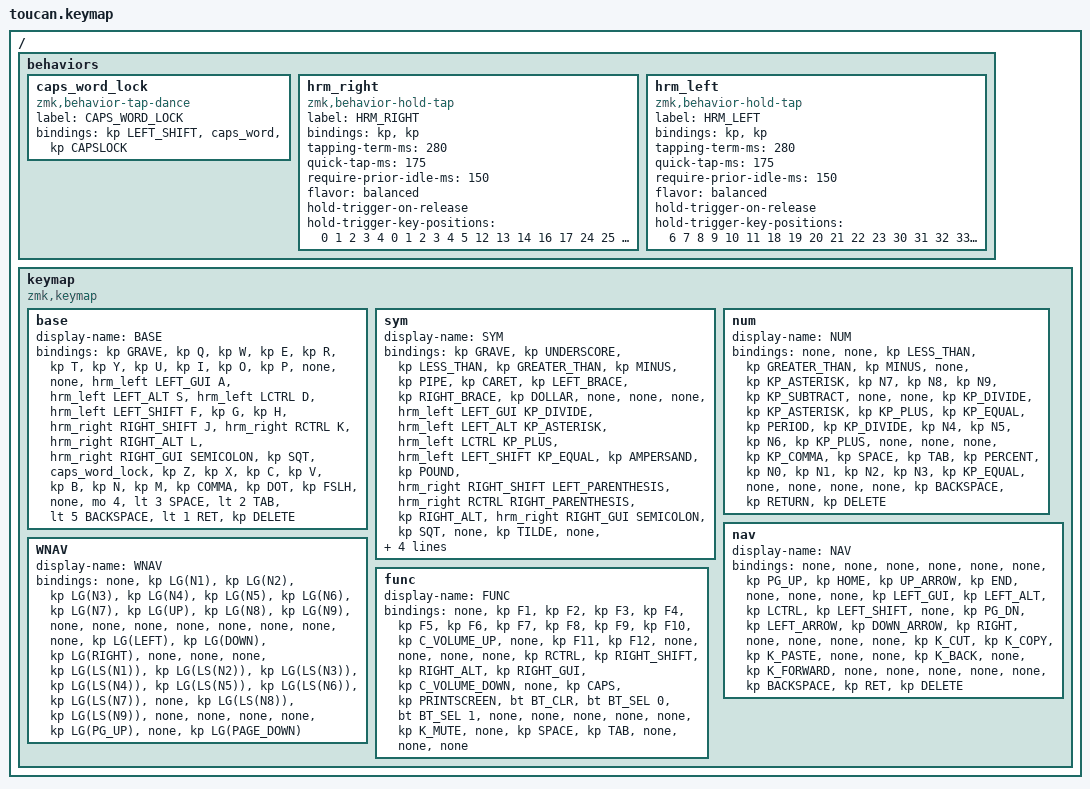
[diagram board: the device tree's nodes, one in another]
#include <behaviors.dtsi>
#include <dt-bindings/zmk/bt.h>
#include <dt-bindings/zmk/keys.h>

#define BASE 0
#define SYM  1
#define NUM  2
#define NAV  3
#define WNAV 4
#define FUNC 5

/ {
    behaviors {
        caps_word_lock: caps_word_lock {
            compatible = "zmk,behavior-tap-dance";
            label = "CAPS_WORD_LOCK";
            #binding-cells = <0>;
            bindings = <&kp LEFT_SHIFT>, <&caps_word>, <&kp CAPSLOCK>;
        };

        hrm_right: hrm_right {
            compatible = "zmk,behavior-hold-tap";
            label = "HRM_RIGHT";
            bindings = <&kp>, <&kp>;

            #binding-cells = <2>;
            tapping-term-ms = <280>;
            quick-tap-ms = <175>;
            require-prior-idle-ms = <150>;
            flavor = "balanced";
            hold-trigger-on-release;
            hold-trigger-key-positions = <0 1 2 3 4 0 1 2 3 4 5 12 13 14 16 17 24 25 26 27 28 29 0 1 2 14 15 36 37 38 39 40 41>;
        };

        hrm_left: hrm_left {
            compatible = "zmk,behavior-hold-tap";
            label = "HRM_LEFT";
            bindings = <&kp>, <&kp>;

            #binding-cells = <2>;
            tapping-term-ms = <280>;
            quick-tap-ms = <175>;
            require-prior-idle-ms = <150>;
            flavor = "balanced";
            hold-trigger-on-release;
            hold-trigger-key-positions = <6 7 8 9 10 11 18 19 20 21 22 23 30 31 32 33 34 35 38 39 40 41 36 37>;
        };
    };

    keymap {
        compatible = "zmk,keymap";

        base {
            display-name = "BASE";
            bindings = <
&kp GRAVE  &kp Q  &kp W  &kp E  &kp R  &kp T  &kp Y  &kp U  &kp I  &kp O  &kp P  &none  &none  &hrm_left LEFT_GUI A  &hrm_left LEFT_ALT S  &hrm_left LCTRL D  &hrm_left LEFT_SHIFT F  &kp G  &kp H  &hrm_right RIGHT_SHIFT J  &hrm_right RCTRL K  &hrm_right RIGHT_ALT L  &hrm_right RIGHT_GUI SEMICOLON  &kp SQT  &caps_word_lock  &kp Z  &kp X  &kp C  &kp V  &kp B  &kp N  &kp M  &kp COMMA  &kp DOT  &kp FSLH  &none  &mo 4  &lt 3 SPACE  &lt 2 TAB  &lt 5 BACKSPACE  &lt 1 RET  &kp DELETE
            >;
        };

        sym {
            display-name = "SYM";
            bindings = <
&kp GRAVE  &kp UNDERSCORE  &kp LESS_THAN  &kp GREATER_THAN  &kp MINUS  &kp PIPE  &kp CARET  &kp LEFT_BRACE  &kp RIGHT_BRACE  &kp DOLLAR  &none  &none  &none  &hrm_left LEFT_GUI KP_DIVIDE  &hrm_left LEFT_ALT KP_ASTERISK  &hrm_left LCTRL KP_PLUS  &hrm_left LEFT_SHIFT KP_EQUAL  &kp AMPERSAND  &kp POUND  &hrm_right RIGHT_SHIFT LEFT_PARENTHESIS  &hrm_right RCTRL RIGHT_PARENTHESIS  &kp RIGHT_ALT  &hrm_right RIGHT_GUI SEMICOLON  &kp SQT  &none  &kp TILDE  &none  &kp LEFT_BRACKET  &kp RIGHT_BRACKET  &kp PERCENT  &kp AT_SIGN  &kp COLON  &kp COMMA  &kp DOT  &kp FSLH  &none  &none  &kp SPACE  &kp TAB  &none  &none  &none
            >;
        };

        num {
            display-name = "NUM";
            bindings = <
&none  &none  &kp LESS_THAN  &kp GREATER_THAN  &kp MINUS  &none  &kp KP_ASTERISK  &kp N7  &kp N8  &kp N9  &kp KP_SUBTRACT  &none  &none  &kp KP_DIVIDE  &kp KP_ASTERISK  &kp KP_PLUS  &kp KP_EQUAL  &kp PERIOD  &kp KP_DIVIDE  &kp N4  &kp N5  &kp N6  &kp KP_PLUS  &none  &none  &none  &kp KP_COMMA  &kp SPACE  &kp TAB  &kp PERCENT  &kp N0  &kp N1  &kp N2  &kp N3  &kp KP_EQUAL  &none  &none  &none  &none  &kp BACKSPACE  &kp RETURN  &kp DELETE
            >;
        };

        nav {
            display-name = "NAV";
            bindings = <
&none  &none  &none  &none  &none  &none  &kp PG_UP  &kp HOME  &kp UP_ARROW  &kp END  &none  &none  &none  &kp LEFT_GUI  &kp LEFT_ALT  &kp LCTRL  &kp LEFT_SHIFT  &none  &kp PG_DN  &kp LEFT_ARROW  &kp DOWN_ARROW  &kp RIGHT  &none  &none  &none  &none  &kp K_CUT  &kp K_COPY  &kp K_PASTE  &none  &none  &kp K_BACK  &none  &kp K_FORWARD  &none  &none  &none  &none  &none  &kp BACKSPACE  &kp RET  &kp DELETE
            >;
        };

        WNAV {
            display-name = "WNAV";
            bindings = <
&none  &kp LG(N1)  &kp LG(N2)  &kp LG(N3)  &kp LG(N4)  &kp LG(N5)  &kp LG(N6)  &kp LG(N7)  &kp LG(UP)  &kp LG(N8)  &kp LG(N9)  &none  &none  &none  &none  &none  &none  &none  &none  &kp LG(LEFT)  &kp LG(DOWN)  &kp LG(RIGHT)  &none  &none  &none  &kp LG(LS(N1))  &kp LG(LS(N2))  &kp LG(LS(N3))  &kp LG(LS(N4))  &kp LG(LS(N5))  &kp LG(LS(N6))  &kp LG(LS(N7))  &none  &kp LG(LS(N8))  &kp LG(LS(N9))  &none  &none  &none  &none  &kp LG(PG_UP)  &none  &kp LG(PAGE_DOWN)
            >;
        };

        func {
            display-name = "FUNC";
            bindings = <
&none  &kp F1  &kp F2  &kp F3  &kp F4  &kp F5  &kp F6  &kp F7  &kp F8  &kp F9  &kp F10  &kp C_VOLUME_UP  &none  &kp F11  &kp F12  &none  &none  &none  &none  &kp RCTRL  &kp RIGHT_SHIFT  &kp RIGHT_ALT  &kp RIGHT_GUI  &kp C_VOLUME_DOWN  &none  &kp CAPS  &kp PRINTSCREEN  &bt BT_CLR  &bt BT_SEL 0  &bt BT_SEL 1  &none  &none  &none  &none  &none  &kp K_MUTE  &none  &kp SPACE  &kp TAB  &none  &none  &none
            >;
        };
    };
};
